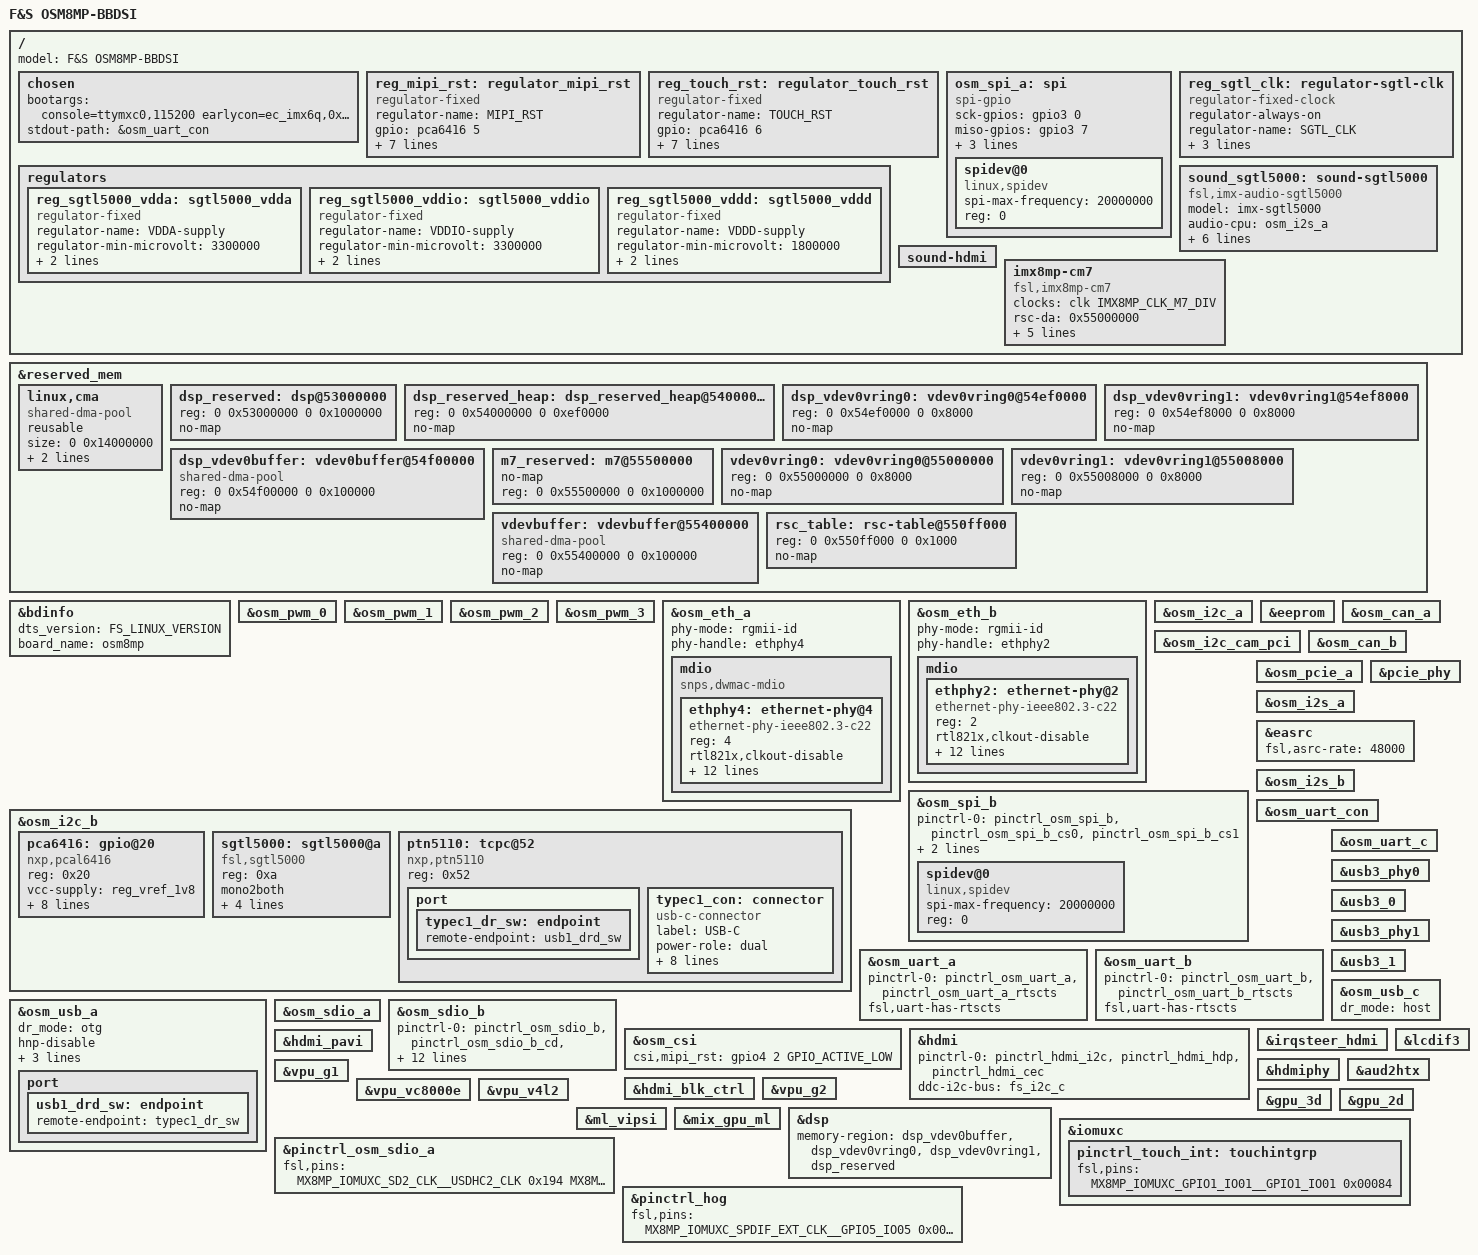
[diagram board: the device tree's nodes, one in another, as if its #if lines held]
/*
 * Copyright (C) 2025 F&S Elektronik Systeme GmbH
 *
 * This program is free software; you can redistribute it and/or modify
 * it under the terms of the GNU General Public License version 2 as
 * published by the Free Software Foundation.
 */

/dts-v1/;

/* Set board revision as 3-digit number, e.g. 110 for board rev. 1.10 */
#define CONFIG_OSM8MP_BOARD_REVISION	110
/* Set adapter revision as 3-digit number, e.g. 110 for board rev. 1.10 */
#define CONFIG_ADP_OSM_BOARD_REVISION	130
/* Set baseboard revision as 3-digit number, e.g. 110 for board rev. 1.10 */
#define CONFIG_PICOCOREBBDSI_BOARD_REVISION	140

/* Activate this if you want to use the Cortex-M4 core */
//#define SUPPORT_M4

/* Display device-trees enables MIPI DSI */
/* MIPI DSI */
//#define CONFIG_OSM8MP_MIPI_DSI

/* CAN */
#define CONFIG_OSM8MP_CAN_A
//#define CONFIG_OSM8MP_CAN_B

/* Network */
#define CONFIG_OSM8MP_ETH_A
#define CONFIG_OSM8MP_ETH_B

/* USB */
#define CONFIG_OSM8MP_USB_A
#define CONFIG_OSM8MP_USB_A_USBC
#define CONFIG_OSM8MP_USB_A_USBC_ALERT
//#define CONFIG_OSM8MP_USB_C

/* PCIe */
#define CONFIG_OSM8MP_PCIE_A

/* I2C */
#define CONFIG_OSM8MP_I2C_A /* OSM: EEPROM BB: I2C_A */
#define CONFIG_OSM8MP_I2C_B /* ADP: SGTL5000 BB: I2C_D */
/* OSM: I2C_CAM_PCI ADP: I2C_CAM  BB: I2C_B */
/* OSM: I2C_CAM_PCI ADP: MPCIE_SM BB: I2C_C */
#define CONFIG_OSM8MP_I2C_CAM_PCI

/* PWM and backlight brightness */
//#define CONFIG_OSM8MP_BL_CTRL
#define CONFIG_OSM8MP_PWM_0
#define CONFIG_OSM8MP_PWM_1

/* UART_CON - ttymxc0 */
#define CONFIG_OSM8MP_UART_CON

/* UART_A - ttymxc1 - Not connected */
//#define CONFIG_OSM8MP_UART_A
//#define CONFIG_OSM8MP_UART_A_RTSCTS

/* UART_B - ttymxc2 */
#define CONFIG_OSM8MP_UART_B
#define CONFIG_OSM8MP_UART_B_RTSCTS

/* UART_C - ttymxc3 */
#define CONFIG_OSM8MP_UART_C

/* FSPI (Single/Dual/Quad) -> Uncommented because of SPI-GPIO */
//#define CONFIG_OSM8MP_SPI_A
#define CONFIG_OSM8MP_SPI_B

/* Audio */
#define CONFIG_OSM8MP_I2S_A
//#define CONFIG_OSM8MP_I2S_B

#define CONFIG_OSM8MP_SGTL5000_AUDIO

/* Camera on serial MIPI CSI interface */
#define CONFIG_OSM8MP_SERIAL_CAMERA
/* Experimental implementation for Basler dart daA3840-30mci.
 * Define CONFIG_OSM8MP_SERIAL_CAMERA must also be set.
 */

/* SDIO */
#define CONFIG_OSM8MP_SDIO_A
#define CONFIG_OSM8MP_SDIO_A_CD
#define CONFIG_OSM8MP_SDIO_A_WP

//#define CONFIG_OSM8MP_SDIO_B
//#define CONFIG_OSM8MP_SDIO_B_CD
//#define CONFIG_OSM8MP_SDIO_B_WP
//#define CONFIG_OSM8MP_SDIO_B_8_Bit

/* Check for invalid CONFIG combinations */

/*
 * Exclude devices from Linux that are used by the Cortex-M4 FreeRTOS examples
 *
 * - UART_D: Debug Console for Cortex-M4
 * - I2C_A:  I2C Bus used in I2C examples
 * - I2C_D:  I2C Bus used by the Audio Codec in SAI examples
 * - SPI_B:  SPI_B is used for ECSPI examples
 * - SDMA1:  Gets removed at another Point, it is used by SPI_B and UART driver
 *           examples
 * - SPI_A:  SPI_A using SDMA1 but SDMA1 is excluded so also exclude SPI_A
 *
 * In addition the following pins are already predefined in FreeRTOS to be used
 * as arbitrary GPIOs. Please remove the comment of the appropriate line of
 * each device from which you use any signal in your own application.
 *
 * - AUDIO_3: GPT capture driver example uses one of its Pins
 */
#ifdef SUPPORT_M4
#undef CONFIG_OSM8MP_UART_C
//#undef CONFIG_OSM8MP_I2C_A
//#undef CONFIG_OSM8MP_SPI_A
//#undef CONFIG_OSM8MP_SPI_B
/* Only undef if using audio/sai examples */
//#undef CONFIG_OSM8MP_I2C_B
//#undef CONFIG_OSM8MP_I2S_A
#endif

/* Disable PWM_0 if BL_CTRL is enabled */
#ifdef CONFIG_OSM8MP_BL_CTRL
#undef CONFIG_OSM8MP_PWM_0
#endif

/* Disable PWM_2 if SPI_A_CS1 is enabled */
#ifdef CONFIG_OSM8MP_SPI_A_CS1
#undef CONFIG_OSM8MP_PWM_2
#endif

/* Disable PWM_2 if SPI_B_CS1 is enabled */
#ifdef CONFIG_OSM8MP_SPI_B_CS1
#undef CONFIG_OSM8MP_PWM_3
#endif

/* Set different settings for corresponding baseboard revision */
#if CONFIG_PICOCOREBBDSI_BOARD_REVISION < 130
#undef CONFIG_OSM8MP_USB_A_USBC
#endif

#if !defined(CONFIG_OSM8MP_USB_A_USBC) \
    || (CONFIG_PICOCOREBBDSI_BOARD_REVISION < 140)
#undef CONFIG_OSM8MP_USB_A_USBC_ALERT
#endif


#include "osm8mp.dts"
#include <fsversion.h>
/ {
	model = "F&S OSM8MP-BBDSI";

	chosen {
		bootargs = "console=ttymxc0,115200 earlycon=ec_imx6q,0x30890000,115200";
		stdout-path = &osm_uart_con;
	};

	reg_mipi_rst: regulator_mipi_rst {
		compatible = "regulator-fixed";
		regulator-name = "MIPI_RST";
		gpio = <&pca6416 5 GPIO_ACTIVE_HIGH>;
		regulator-min-microvolt = <3300000>;
		regulator-max-microvolt = <3300000>;
		regulator-boot-on;
		regulator-always-on;
		enable-active-high;
		startup-delay-us = <1000>;
		off-on-delay-us = <12000>;
	};

	reg_touch_rst: regulator_touch_rst {
		compatible = "regulator-fixed";
		regulator-name = "TOUCH_RST";
		gpio = <&pca6416 6 GPIO_ACTIVE_HIGH>;
		regulator-min-microvolt = <3300000>;
		regulator-max-microvolt = <3300000>;
		regulator-boot-on;
		regulator-always-on;
		enable-active-high;
		startup-delay-us = <1000>;
		off-on-delay-us = <12000>;
	};

};

&reserved_mem {
	#address-cells = <2>;
	#size-cells = <2>;
	ranges;

	linux,cma {
		compatible = "shared-dma-pool";
		reusable;
		size = <0 0x14000000>;
		alloc-ranges = <0 0x40000000 0 0x40000000>;
		linux,cma-default;
	};
};

&bdinfo{
	dts_version = FS_LINUX_VERSION;
	board_name = "osm8mp";
};

#if defined(CONFIG_OSM8MP_BL_CTRL) || defined(CONFIG_OSM8MP_PWM_0)
&osm_pwm_0 { status = "okay"; };
#endif /* CONFIG_OSM8MP_BL_CTRL || CONFIG_OSM8MP_PWM_0 */

#ifdef CONFIG_OSM8MP_PWM_1
&osm_pwm_1 { status = "okay"; };
#endif /* CONFIG_OSM8MP_PWM_1 */

#ifdef CONFIG_OSM8MP_PWM_2
&osm_pwm_2 { status = "okay"; };
#endif /* CONFIG_OSM8MP_PWM_2 */

#ifdef CONFIG_OSM8MP_PWM_3
&osm_pwm_3 { status = "okay"; };
#endif /* CONFIG_OSM8MP_PWM_3 */

#ifdef CONFIG_OSM8MP_ETH_A
&osm_eth_a {
	phy-mode = "rgmii-id";
	phy-handle = <&ethphy4>;
	status = "okay";

	mdio {
		compatible = "snps,dwmac-mdio";
		#address-cells = <1>;
		#size-cells = <0>;

		ethphy4: ethernet-phy@4 {
			compatible = "ethernet-phy-ieee802.3-c22";
			reg = <4>;
			rtl821x,clkout-disable;
			rtl821x,aldps-enable;
			rtl821x,ssc-rxc-enable;
			rtl821x,ssc-sysclk-enable;
			rtl821x,ssc-clkout-enable;
			rtl821x,led-link = <2>; // LED1 for link indication
			rtl821x,led-act = <2>; // LED1 for activity
			reset-gpios = <&pca6416 0 GPIO_ACTIVE_LOW>;
			reset-assert-us = <10000>;
			reset-deassert-us = <100000>;
			interrupt-parent = <&pca6416>;
			interrupts = <2 IRQ_TYPE_EDGE_FALLING>;
			eee-broken-1000t;
		};
	};
};
#endif /* CONFIG_OSM8MP_ETH_A */

#ifdef CONFIG_OSM8MP_ETH_B
&osm_eth_b {
	phy-mode = "rgmii-id";
	phy-handle = <&ethphy2>;
	status = "okay";

	mdio {
		#address-cells = <1>;
		#size-cells = <0>;

		ethphy2: ethernet-phy@2 {
			compatible = "ethernet-phy-ieee802.3-c22";
			reg = <2>;
			rtl821x,clkout-disable;
			rtl821x,aldps-enable;
			rtl821x,ssc-rxc-enable;
			rtl821x,ssc-sysclk-enable;
			rtl821x,ssc-clkout-enable;
			rtl821x,led-link = <2>; // LED1 for link indication
			rtl821x,led-act = <2>; // LED1 for activity
			reset-gpios = <&pca6416 1 GPIO_ACTIVE_LOW>;
			reset-assert-us = <10000>;
			reset-deassert-us = <100000>;
			interrupt-parent = <&pca6416>;
			interrupts = <3 IRQ_TYPE_EDGE_FALLING>;
			eee-broken-1000t;
		};
	};
};
#endif /* CONFIG_OSM8MP_ETH_B */

#ifdef CONFIG_OSM8MP_I2C_A
&osm_i2c_a { status = "okay"; };
#ifdef CONFIG_OSM8MP_EEPROM
&eeprom { status = "okay"; };
#endif /* CONFIG_OSM8MP_EEPROM */
#endif /* CONFIG_OSM8MP_I2C_A */

#ifdef CONFIG_OSM8MP_I2C_B
&osm_i2c_b { status = "okay"; };
#if CONFIG_ADP_OSM_BOARD_REVISION >= 130
&osm_i2c_b {
	/* GPIO expander */
	pca6416: gpio@20 {
		compatible = "nxp,pcal6416";
		reg = <0x20>;
		vcc-supply = <&reg_vref_1v8>;
		gpio-controller;
		#gpio-cells = <2>;
		interrupt-controller;
		#interrupt-cells = <2>;
		interrupt-parent = <&gpio1>;
		interrupts = <6 IRQ_TYPE_LEVEL_LOW>;
		/* Enable Open-Drain for Port 0 and 1 */
		pcal6416,open-drain;
		gpio-line-names =
		/*  0 */ "", "", "", "",
		/*  4 */ "AUDIO_B_I2S_RXFS", "GPIO_J1_7", "GPIO_J1_2", "BL_ON",
		/*  8 */ "VLCD_ON", "GPIO_J1_44", "GPIO_J1_46", "",
		/* 12 */ "", "", "", "";
		status = "okay";
	};
};
#endif /* CONFIG_ADP_OSM_BOARD_REVISION >= 130 */
#endif /* CONFIG_OSM8MP_I2C_B */

#ifdef CONFIG_OSM8MP_I2C_CAM_PCI
&osm_i2c_cam_pci { status = "okay"; };
#endif /* CONFIG_OSM8MP_I2C_CAM_PCI */

#ifdef CONFIG_OSM8MP_SPI_A
/ {
	/* osm_spi_a overwritten by SPI bitbanging driver */
	/delete-node/ &osm_spi_a;
	/* SPI bitbanging driver */
	osm_spi_a: spi {
		compatible = "spi-gpio";
		#address-cells = <0x1>;
		#size-cells = <0x0>;

		sck-gpios = <&gpio3 0 0>;
		miso-gpios = <&gpio3 7 0>;
		mosi-gpios = <&gpio3 6 0>;
		cs-gpios = <&gpio3 1 0>;
		num-chipselects = <1>;

		spidev@0 {
			compatible = "linux,spidev";
			spi-max-frequency = <20000000>;
			reg = <0>;
			status = "okay";
		};
	};
};
#endif /* CONFIG_OSM8MP_SPI_A */

#ifdef CONFIG_OSM8MP_SPI_B
&osm_spi_b {
#ifdef CONFIG_OSM8MP_SPI_B_CS1
	pinctrl-0 = <&pinctrl_osm_spi_b &pinctrl_osm_spi_b_cs0 &pinctrl_osm_spi_b_cs1>;
	cs-gpios = <&gpio5 13 GPIO_ACTIVE_LOW>, <&gpio3 20 GPIO_ACTIVE_LOW>;
	num-cs = <2>;
#else
	pinctrl-0 = <&pinctrl_osm_spi_b &pinctrl_osm_spi_b_cs0>;
	cs-gpios = <&gpio5 13 GPIO_ACTIVE_LOW>;
	num-cs = <1>;
#endif
	status = "okay";

	spidev@0 {
		compatible = "linux,spidev";
		spi-max-frequency = <20000000>;
		reg = <0>;
		status = "okay";
	};
};
#endif


#ifdef CONFIG_OSM8MP_CAN_A
&osm_can_a { status = "okay"; };
#endif /* CONFIG_OSM8MP_CAN_A */

#ifdef CONFIG_OSM8MP_CAN_B
&osm_can_b { status = "okay"; };
#endif /* CONFIG_OSM8MP_CAN_B */

#ifdef CONFIG_OSM8MP_PCIE_A
&osm_pcie_a{ status = "okay";};
&pcie_phy{ status = "okay";};
#endif /* CONFIG_OSM8MP_PCIE_A */

#ifdef CONFIG_OSM8MP_I2S_A
&osm_i2s_a { status = "okay"; };

#ifdef CONFIG_OSM8MP_SGTL5000_AUDIO
/{
	regulators {
		/* SGTL5000 analog voltage */
		reg_sgtl5000_vdda: sgtl5000_vdda {
			compatible = "regulator-fixed";
			regulator-name = "VDDA-supply";
			regulator-min-microvolt = <3300000>;
			regulator-max-microvolt = <3300000>;
			regulator-always-on;
		};

		/* SGTL5000 I/O voltage */
		reg_sgtl5000_vddio: sgtl5000_vddio {
			compatible = "regulator-fixed";
			regulator-name = "VDDIO-supply";
			regulator-min-microvolt = <3300000>;
			regulator-max-microvolt = <3300000>;
			regulator-always-on;
		};

		/* SGTL5000 internal digital voltage */
		reg_sgtl5000_vddd: sgtl5000_vddd {
			compatible = "regulator-fixed";
			regulator-name = "VDDD-supply";
			regulator-min-microvolt = <1800000>;
			regulator-max-microvolt = <1800000>;
			regulator-always-on;
		};
	};

	reg_sgtl_clk: regulator-sgtl-clk {
			compatible = "regulator-fixed-clock";
			regulator-always-on;
			regulator-name = "SGTL_CLK";
			clocks = <&clk IMX8MP_CLK_CLKOUT1>;
			assigned-clocks = <&clk IMX8MP_CLK_CLKOUT1>;
			assigned-clock-rates = <24576000>;
	};

	sound_sgtl5000: sound-sgtl5000 {
		compatible = "fsl,imx-audio-sgtl5000";
		model = "imx-sgtl5000";
		audio-cpu = <&osm_i2s_a>;
		audio-codec = <&sgtl5000>;
		audio-asrc = <&easrc>;
		audio-routing =
			"LINE_IN", "Line In Jack",
			"Mic Jack", "Mic Bias",
			"MIC_IN", "Mic Jack",
			"Line Out Jack", "LINE_OUT",
			"Headphone Jack", "HP_OUT";
	};
};

&osm_i2c_b {
	status = "okay";
	sgtl5000: sgtl5000@a {
		compatible = "fsl,sgtl5000";
		reg = <0xa>;
		mono2both;
		clocks = <&clk IMX8MP_CLK_CLKOUT1>;
		VDDA-supply = <&reg_sgtl5000_vdda>;
		VDDIO-supply = <&reg_sgtl5000_vddio>;
		VDDD-supply = <&reg_sgtl5000_vddd>;
	};
};

&easrc {
	fsl,asrc-rate  = <48000>;
	status = "okay";
};
#endif /* CONFIG_OSM8MP_SGTL5000_AUDIO */
#endif /* CONFIG_OSM8MP_I2S_A */

#ifdef CONFIG_OSM8MP_I2S_B
&osm_i2s_b { status = "okay"; };
#endif /* CONFIG_OSM8MP_I2S_B */

#ifdef CONFIG_OSM8MP_UART_CON
&osm_uart_con { status = "okay"; };
#endif /* CONFIG_OSM8MP_UART_CON */

#ifdef CONFIG_OSM8MP_UART_A
&osm_uart_a {
#ifdef CONFIG_OSM8MP_UART_A_RTSCTS
	pinctrl-0 = <&pinctrl_osm_uart_a &pinctrl_osm_uart_a_rtscts>;
	fsl,uart-has-rtscts;
#endif
	status = "okay";
};
#endif /* CONFIG_OSM8MP_UART_A */

#ifdef CONFIG_OSM8MP_UART_B
&osm_uart_b {
#ifdef CONFIG_OSM8MP_UART_B_RTSCTS
	pinctrl-0 = <&pinctrl_osm_uart_b &pinctrl_osm_uart_b_rtscts>;
	fsl,uart-has-rtscts;
#endif
	status = "okay";
};
#endif /* CONFIG_OSM8MP_UART_B */

#ifdef CONFIG_OSM8MP_UART_C
&osm_uart_c { status = "okay"; };
#endif /* CONFIG_OSM8MP_UART_C */

#ifdef CONFIG_OSM8MP_USB_A
&usb3_phy0 { status = "okay"; };

&usb3_0 { status = "okay"; };

&osm_usb_a {
	dr_mode = "otg";
#ifdef CONFIG_OSM8MP_USB_A_USBC
	hnp-disable;
	srp-disable;
	adp-disable;
	usb-role-switch;
	status = "okay";
	port {
		usb1_drd_sw: endpoint {
			remote-endpoint = <&typec1_dr_sw>;
		};
	};
#endif
};

#ifdef CONFIG_OSM8MP_USB_A_USBC
&osm_i2c_b {
	/* USB-C */
	ptn5110: tcpc@52 {
		compatible = "nxp,ptn5110";
#ifdef CONFIG_OSM8MP_USB_A_USBC_ALERT
#if CONFIG_ADP_OSM_BOARD_REVISION < 130
		interrupt-parent = <&gpio1>;
		interrupts = <10 IRQ_TYPE_LEVEL_LOW>;
#endif
#endif
		reg = <0x52>;
		status = "okay";

		port {
			typec1_dr_sw: endpoint {
				remote-endpoint = <&usb1_drd_sw>;
			};
		};

		typec1_con: connector {
			compatible = "usb-c-connector";
			label = "USB-C";
			power-role = "dual";
			data-role = "dual";
			try-power-role = "sink";
			source-pdos = <PDO_FIXED(5000, 3000,
			PDO_FIXED_USB_COMM)>;
			sink-pdos = <PDO_FIXED(5000, 3000, PDO_FIXED_USB_COMM)
				     PDO_VAR(5000, 20000, 3000)>;
			op-sink-microwatt = <15000000>;
			self-powered;
		};
	};
};
#endif  /* CONFIG_OSM8MP_USB_A_USBC */
#endif  /* CONFIG_OSM8MP_USB_A */

#ifdef CONFIG_OSM8MP_USB_C
&usb3_phy1 {
	status = "okay";
};

&usb3_1 {
	status = "okay";
};

&osm_usb_c {
	dr_mode = "host";
	status = "okay";
};
#endif /* CONFIG_OSM8MP_USB_C */

#ifdef CONFIG_OSM8MP_SDIO_A
&osm_sdio_a { status = "okay"; };
#endif /* CONFIG_OSM8MP_SDIO_A */

#ifdef CONFIG_OSM8MP_SDIO_B
&osm_sdio_b {
	pinctrl-0 = <&pinctrl_osm_sdio_b>, <&pinctrl_osm_sdio_b_cd>, <&pinctrl_osm_sdio_b_wp>, <&pinctrl_osm_sdio_b_rst>;
	pinctrl-1 = <&pinctrl_osm_sdio_b_100mhz>, <&pinctrl_osm_sdio_b_cd>, <&pinctrl_osm_sdio_b_wp>, <&pinctrl_osm_sdio_b_rst>;
	pinctrl-2 = <&pinctrl_osm_sdio_b_200mhz>, <&pinctrl_osm_sdio_b_cd>, <&pinctrl_osm_sdio_b_wp>, <&pinctrl_osm_sdio_b_rst>;
	vqmmc-supply = <&reg_vref_1v8>;
#ifdef CONFIG_OSM8MP_SDIO_B_8_Bit
	bus-width = <8>;
#else
	bus-width = <4>;
#endif
	status = "okay";
};
#endif

#ifdef CONFIG_OSM8MP_SERIAL_CAMERA
&osm_csi {
	status = "okay";
	csi,mipi_rst = <&gpio4 2 GPIO_ACTIVE_LOW>;
};
#endif

#ifdef CONFIG_OSM8MP_HDMI
&hdmi {

pinctrl-0 =<
#ifdef CONFIG_OSM8MP_HDMI_I2C
			&pinctrl_hdmi_i2c
#endif
#ifdef CONFIG_OSM8MP_HDMI_HPD
			&pinctrl_hdmi_hdp
#endif
#ifdef CONFIG_OSM8MP_HDMI_CEC
			&pinctrl_hdmi_cec
#endif
			>;

#ifndef CONFIG_OSM8MP_HDMI_I2C
	ddc-i2c-bus = <&fs_i2c_c>;
#endif
	status = "okay";

};

&irqsteer_hdmi { status = "okay"; };
&hdmi_pavi { status = "okay"; };
&hdmi { status="okay"; };
&hdmiphy { status="okay"; };
&hdmi_blk_ctrl { status="okay"; };
&lcdif3 { status = "okay"; };

#ifdef CONFIG_OSM8MP_HDMI_AUDIO
/{
	sound-hdmi { status = "okay"; };
};
&aud2htx { status = "okay"; };
#endif /* CONFIG_OSM8MP_HDMI_AUDIO */
#endif /* CONFIG_OSM8MP_HDMI */

#ifdef CONFIG_OSM8MP_VPU
&vpu_g1 { status = "okay"; };
&vpu_g2 { status = "okay"; };
&vpu_vc8000e { status = "okay"; };
&vpu_v4l2 { status = "okay"; };
#endif /* CONFIG_OSM8MP_VPU */

#ifdef CONFIG_OSM8MP_GPU
&gpu_3d { status = "okay"; };
&gpu_2d { status = "okay"; };
#endif /* CONFIG_OSM8MP_GPU */

#ifdef CONFIG_OSM8MP_ML
&ml_vipsi { status = "okay"; };
&mix_gpu_ml { status = "okay"; };
#endif /* CONFIG_OSM8MP_ML */

#ifdef CONFIG_OSM8MP_DSP
&reserved_mem {
	dsp_reserved: dsp@53000000 {
		reg = <0 0x53000000 0 0x1000000>;
		no-map;
	};
	dsp_reserved_heap: dsp_reserved_heap@54000000 {
		reg = <0 0x54000000 0 0xef0000>;
		no-map;
	};
	dsp_vdev0vring0: vdev0vring0@54ef0000 {
		reg = <0 0x54ef0000 0 0x8000>;
		no-map;
	};
	dsp_vdev0vring1: vdev0vring1@54ef8000 {
		reg = <0 0x54ef8000 0 0x8000>;
		no-map;
	};
	dsp_vdev0buffer: vdev0buffer@54f00000{
		compatible = "shared-dma-pool";
		reg = <0 0x54f00000 0 0x100000>;
		no-map;
	};
};

&dsp {
	memory-region = <&dsp_vdev0buffer>, <&dsp_vdev0vring0>,
			<&dsp_vdev0vring1>, <&dsp_reserved>;
	status = "okay";
};
#endif /* CONFIG_OSM8MP_DSP */

#ifdef SUPPORT_M7
&reserved_mem {
	#address-cells = <2>;
	#size-cells = <2>;
	ranges;

		m7_reserved: m7@55500000 {
			no-map;
			reg = <0 0x55500000 0 0x1000000>;
		};

		vdev0vring0: vdev0vring0@55000000 {
			reg = <0 0x55000000 0 0x8000>;
			no-map;
		};

		vdev0vring1: vdev0vring1@55008000 {
			reg = <0 0x55008000 0 0x8000>;
			no-map;
		};

		vdevbuffer: vdevbuffer@55400000 {
			compatible = "shared-dma-pool";
			reg = <0 0x55400000 0 0x100000>;
			no-map;
		};

		rsc_table: rsc-table@550ff000 {
			reg = <0 0x550ff000 0 0x1000>;
			no-map;
		};
};

/ {
	imx8mp-cm7 {
		compatible = "fsl,imx8mp-cm7";
		clocks = <&clk IMX8MP_CLK_M7_DIV>;
		rsc-da = <0x55000000>;
		mbox-names = "tx", "rx", "rxdb";
		mboxes = <&mu 0 1
			  &mu 1 1
			  &mu 3 1>;
		memory-region = <&m7_reserved>, <&vdevbuffer>, <&vdev0vring0>, <&vdev0vring1>, <&rsc_table>;
		status = "okay";
		fsl,startup-delay-ms = <500>;
	};
};
#endif /* SUPPORT_M7 */

&iomuxc {
	pinctrl_touch_int: touchintgrp {
		fsl,pins = <
			MX8MP_IOMUXC_GPIO1_IO01__GPIO1_IO01	0x00084
		>;
	};
};

/*
 * MK 2025-09-18:
 * The drive-strength for SDIO_A must be increased to compensate
 * for a longer route through the adapter (OSM -> ADP -> BB)
 */
&pinctrl_osm_sdio_a {
	fsl,pins = <
		MX8MP_IOMUXC_SD2_CLK__USDHC2_CLK	0x194
		MX8MP_IOMUXC_SD2_CMD__USDHC2_CMD	0x1d4
		MX8MP_IOMUXC_SD2_DATA0__USDHC2_DATA0	0x1d4
		MX8MP_IOMUXC_SD2_DATA1__USDHC2_DATA1	0x1d4
		MX8MP_IOMUXC_SD2_DATA2__USDHC2_DATA2	0x1d4
		MX8MP_IOMUXC_SD2_DATA3__USDHC2_DATA3	0x1d4
	>;
};

&pinctrl_hog {
	fsl,pins = <
		/* CARRIER_PWR_EN */
		MX8MP_IOMUXC_SPDIF_EXT_CLK__GPIO5_IO05	0x00004

		/* GPIO_A */
#ifndef IMX8MP_TOUCH_INTERRUPT_PINCTRL
		/* 0 */ MX8MP_IOMUXC_GPIO1_IO05__GPIO1_IO05	0x00004
		/* 3 */ MX8MP_IOMUXC_GPIO1_IO01__GPIO1_IO01	0x00004
#else
#if CONFIG_ADP_OSM_BOARD_REVISION < 130
		/* 0 */ MX8MP_IOMUXC_GPIO1_IO05__GPIO1_IO05	0x00004
#else
		/* 3 */ MX8MP_IOMUXC_GPIO1_IO01__GPIO1_IO01	0x00004
#endif
#endif
		/* 1 */ MX8MP_IOMUXC_GPIO1_IO06__GPIO1_IO06	0x00004
		/* 2 */ MX8MP_IOMUXC_GPIO1_IO07__GPIO1_IO07	0x00004
		/* 4 */ MX8MP_IOMUXC_GPIO1_IO10__GPIO1_IO10	0x00004
		/* 5 */ MX8MP_IOMUXC_GPIO1_IO08__GPIO1_IO08	0x00004
#ifndef CONFIG_OSM8MP_PWM_2
#ifndef CONFIG_OSM8MP_SPI_A_CS1
		/* 6 */ MX8MP_IOMUXC_SAI5_RXD0__GPIO3_IO21	0x00004
#endif
#endif
#ifndef CONFIG_OSM8MP_PWM_3
#ifndef CONFIG_OSM8MP_SPI_B_CS1
		/* 7 */ MX8MP_IOMUXC_SAI5_RXC__GPIO3_IO20	0x00004
#endif
#endif
		/* GPIO_B */
		/* 0 */ MX8MP_IOMUXC_GPIO1_IO03__GPIO1_IO03	0x00004
		/* 1 */ MX8MP_IOMUXC_GPIO1_IO11__GPIO1_IO11	0x00004
		/* 2 */ MX8MP_IOMUXC_GPIO1_IO00__GPIO1_IO00	0x00004
		/* 3 */ MX8MP_IOMUXC_GPIO1_IO09__GPIO1_IO09	0x00004
		/* 4 */ MX8MP_IOMUXC_SAI5_RXD3__GPIO3_IO24	0x00004
		/* 5 */ MX8MP_IOMUXC_SAI2_RXC__GPIO4_IO22	0x00004
		/* 6 */ MX8MP_IOMUXC_SAI5_RXD2__GPIO3_IO23	0x00004
		/* 7 */ MX8MP_IOMUXC_SAI2_RXFS__GPIO4_IO21	0x00004

		/* GPIO_C */
		/* 0 */ MX8MP_IOMUXC_SAI2_MCLK__GPIO4_IO27	0x00004
		/* 1 */ MX8MP_IOMUXC_SAI1_RXD1__GPIO4_IO03	0x00004
		/* 2 */ MX8MP_IOMUXC_SAI1_TXD7__GPIO4_IO19	0x00004
		/* 3 */ MX8MP_IOMUXC_SAI1_TXD6__GPIO4_IO18	0x00004
		/* 4 */ /* VDD_EN: Disable display for usage */
		/* 4 */ MX8MP_IOMUXC_SAI1_RXFS__GPIO4_IO00	0x00004
		/* 5 */ /* BL_EN: Disable backlight control for usage */
		/* 5 */ MX8MP_IOMUXC_SAI1_MCLK__GPIO4_IO20	0x00004
		/* 6 */ /* CAM_EN: Disable CAM for usage */
		/* 6 */ MX8MP_IOMUXC_SAI1_RXC__GPIO4_IO01	0x00004
		/* 7 */ /* CAM_RST: Disable CAM for usage */
		/* 7 */ MX8MP_IOMUXC_SAI1_RXD0__GPIO4_IO02	0x00004

#if !defined(CONFIG_OSM8MP_BL_CTRL) && !defined(CONFIG_OSM8MP_PWM_0)
		MX8MP_IOMUXC_SAI5_RXFS__GPIO3_IO19	0x00004
#endif

#ifndef CONFIG_OSM8MP_PWM_1
		MX8MP_IOMUXC_SAI5_MCLK__GPIO3_IO25	0x00004
#endif

#ifndef CONFIG_OSM8MP_SPI_A
		MX8MP_IOMUXC_NAND_ALE__GPIO3_IO00		0x00004
		MX8MP_IOMUXC_NAND_DATA00__GPIO3_IO06	0x00004
		MX8MP_IOMUXC_NAND_DATA01__GPIO3_IO07	0x00004
		MX8MP_IOMUXC_NAND_DATA02__GPIO3_IO08	0x00004
		MX8MP_IOMUXC_NAND_DATA03__GPIO3_IO09	0x00004
		MX8MP_IOMUXC_NAND_CE0_B__GPIO3_IO01		0x00004
#endif
#ifndef CONFIG_OSM8MP_SPI_A_HIGHSPEED
		/* Enable DSI_TE functionality */
		MX8MP_IOMUXC_NAND_DQS__GPIO3_IO14		0x00004
#endif

#ifndef CONFIG_OSM8MP_SPI_B
		MX8MP_IOMUXC_ECSPI2_SCLK__GPIO5_IO10	0x00004
		MX8MP_IOMUXC_ECSPI2_MOSI__GPIO5_IO11	0x00004
		MX8MP_IOMUXC_ECSPI2_MISO__GPIO5_IO12	0x00004
		MX8MP_IOMUXC_ECSPI1_SS0__GPIO5_IO09		0x00004
#endif

#ifndef CONFIG_OSM8MP_ETH_A
		MX8MP_IOMUXC_ENET_MDC__GPIO1_IO16		0x00004
		MX8MP_IOMUXC_ENET_MDIO__GPIO1_IO17		0x00004
		MX8MP_IOMUXC_ENET_RD0__GPIO1_IO26		0x00004
		MX8MP_IOMUXC_ENET_RD1__GPIO1_IO27		0x00004
		MX8MP_IOMUXC_ENET_RD2__GPIO1_IO28		0x00004
		MX8MP_IOMUXC_ENET_RD3__GPIO1_IO29		0x00004
		MX8MP_IOMUXC_ENET_RXC__GPIO1_IO25		0x00004
		MX8MP_IOMUXC_ENET_RX_CTL__GPIO1_IO24	0x00004
		MX8MP_IOMUXC_ENET_TD0__GPIO1_IO21		0x00004
		MX8MP_IOMUXC_ENET_TD1__GPIO1_IO20		0x00004
		MX8MP_IOMUXC_ENET_TD2__GPIO1_IO19		0x00004
		MX8MP_IOMUXC_ENET_TD3__GPIO1_IO18		0x00004
		MX8MP_IOMUXC_ENET_TX_CTL__GPIO1_IO22	0x00004
		MX8MP_IOMUXC_ENET_TXC__GPIO1_IO23		0x00004
#endif

#ifndef CONFIG_OSM8MP_ETH_B
		MX8MP_IOMUXC_SAI1_RXD2__GPIO4_IO04	0x00004
		MX8MP_IOMUXC_SAI1_RXD3__GPIO4_IO05	0x00004
		MX8MP_IOMUXC_SAI1_RXD4__GPIO4_IO06	0x00004
		MX8MP_IOMUXC_SAI1_RXD5__GPIO4_IO07	0x00004
		MX8MP_IOMUXC_SAI1_RXD6__GPIO4_IO08	0x00004
		MX8MP_IOMUXC_SAI1_RXD7__GPIO4_IO09	0x00004
		MX8MP_IOMUXC_SAI1_TXC__GPIO4_IO11	0x00004
		MX8MP_IOMUXC_SAI1_TXFS__GPIO4_IO10	0x00004
		MX8MP_IOMUXC_SAI1_TXD0__GPIO4_IO12	0x00004
		MX8MP_IOMUXC_SAI1_TXD1__GPIO4_IO13	0x00004
		MX8MP_IOMUXC_SAI1_TXD2__GPIO4_IO14	0x00004
		MX8MP_IOMUXC_SAI1_TXD3__GPIO4_IO15	0x00004
		MX8MP_IOMUXC_SAI1_TXD4__GPIO4_IO16	0x00004
		MX8MP_IOMUXC_SAI1_TXD5__GPIO4_IO17	0x00004
#endif

#ifndef CONFIG_OSM8MP_CAN_A
		MX8MP_IOMUXC_SPDIF_RX__GPIO5_IO04	0x00004
		MX8MP_IOMUXC_SPDIF_TX__GPIO5_IO03	0x00004
#endif

#ifndef CONFIG_OSM8MP_CAN_B
		MX8MP_IOMUXC_HDMI_HPD__GPIO3_IO29	0x00004
		MX8MP_IOMUXC_HDMI_CEC__GPIO3_IO28	0x00004
#endif

#ifndef CONFIG_OSM8MP_I2C_A
		MX8MP_IOMUXC_I2C3_SCL__GPIO5_IO18		0x00004
		MX8MP_IOMUXC_I2C3_SDA__GPIO5_IO19		0x00004
#endif

#ifndef CONFIG_OSM8MP_I2C_B
		MX8MP_IOMUXC_I2C4_SCL__GPIO5_IO20		0x00004
		MX8MP_IOMUXC_I2C4_SDA__GPIO5_IO21		0x00004
#endif

#ifndef CONFIG_OSM8MP_I2C_CAM_PCI
		MX8MP_IOMUXC_HDMI_DDC_SCL__GPIO3_IO26	0x00004
		MX8MP_IOMUXC_HDMI_DDC_SDA__GPIO3_IO27	0x00004
#endif

#ifndef CONFIG_OSM8MP_PCIE_A
		MX8MP_IOMUXC_SAI5_RXD1__GPIO3_IO22		0x00004
		MX8MP_IOMUXC_SAI3_RXC__GPIO4_IO29		0x00004
		MX8MP_IOMUXC_SAI3_RXFS__GPIO4_IO28		0x00004
		MX8MP_IOMUXC_NAND_CE1_B__GPIO3_IO02		0x00004
#endif

#ifndef CONFIG_OSM8MP_I2S_A
		MX8MP_IOMUXC_SAI2_TXFS__GPIO4_IO24	0x00004
		MX8MP_IOMUXC_SAI2_TXC__GPIO4_IO25	0x00004
		MX8MP_IOMUXC_SAI2_TXD0__GPIO4_IO26	0x00004
		MX8MP_IOMUXC_SAI2_RXD0__GPIO4_IO23	0x00004
#endif

#ifndef CONFIG_OSM8MP_I2S_B
		MX8MP_IOMUXC_SAI3_TXFS__GPIO4_IO31	0x00004
		MX8MP_IOMUXC_SAI3_TXC__GPIO5_IO00	0x00004
		MX8MP_IOMUXC_SAI3_TXD__GPIO5_IO01	0x00004
		MX8MP_IOMUXC_SAI3_RXD__GPIO4_IO30	0x00004
#endif

#ifndef CONFIG_OSM8MP_UART_A
		MX8MP_IOMUXC_UART1_RXD__GPIO5_IO22		0x00004
		MX8MP_IOMUXC_UART1_TXD__GPIO5_IO23		0x00004
#endif
#ifndef CONFIG_OSM8MP_UART_A_RTSCTS
		MX8MP_IOMUXC_UART3_RXD__GPIO5_IO26		0x00004
		MX8MP_IOMUXC_UART3_TXD__GPIO5_IO27		0x00004
#endif

#ifndef CONFIG_OSM8MP_UART_B
		MX8MP_IOMUXC_ECSPI1_SCLK__GPIO5_IO06 	0x00004
		MX8MP_IOMUXC_ECSPI1_MOSI__GPIO5_IO07	0x00004
#endif
#ifndef CONFIG_OSM8MP_UART_B_RTSCTS
		MX8MP_IOMUXC_ECSPI1_MISO__GPIO5_IO08	0x00004
		MX8MP_IOMUXC_ECSPI1_SS0__GPIO5_IO09		0x00004
#endif

#ifndef CONFIG_OSM8MP_UART_C
		MX8MP_IOMUXC_UART4_RXD__GPIO5_IO28		0x00004
		MX8MP_IOMUXC_UART4_TXD__GPIO5_IO29		0x00004
#endif

#ifndef CONFIG_OSM8MP_UART_CON
		MX8MP_IOMUXC_UART2_RXD__GPIO5_IO24		0x00004
		MX8MP_IOMUXC_UART2_TXD__GPIO5_IO25		0x00004
#endif

#ifndef CONFIG_OSM8MP_USB_A
		MX8MP_IOMUXC_GPIO1_IO12__GPIO1_IO12	0x00004
#endif

#ifndef CONFIG_OSM8MP_USB_C
		MX8MP_IOMUXC_GPIO1_IO14__GPIO1_IO14	0x00004
#endif

#ifndef CONFIG_OSM8MP_SDIO_A
		MX8MP_IOMUXC_SD2_RESET_B__GPIO2_IO19	0x00004
		MX8MP_IOMUXC_SD2_CLK__GPIO2_IO13		0x00004
		MX8MP_IOMUXC_SD2_CMD__GPIO2_IO14		0x00004
		MX8MP_IOMUXC_SD2_DATA0__GPIO2_IO15		0x00004
		MX8MP_IOMUXC_SD2_DATA1__GPIO2_IO16		0x00004
		MX8MP_IOMUXC_SD2_DATA2__GPIO2_IO17		0x00004
		MX8MP_IOMUXC_SD2_DATA3__GPIO2_IO18		0x00004
#endif
#ifndef CONFIG_OSM8MP_SDIO_A_CD
		MX8MP_IOMUXC_SD2_CD_B__GPIO2_IO12		0x00004
#endif
#ifndef CONFIG_OSM8MP_SDIO_A_WP
		MX8MP_IOMUXC_SD2_WP__GPIO2_IO20			0x00004
#endif

#ifndef CONFIG_OSM8MP_SDIO_B
			MX8MP_IOMUXC_NAND_READY_B__GPIO3_IO16	0x00004
			MX8MP_IOMUXC_NAND_WE_B__GPIO3_IO17		0x00004
			MX8MP_IOMUXC_NAND_WP_B__GPIO3_IO18		0x00004
			MX8MP_IOMUXC_NAND_DATA04__GPIO3_IO10	0x00004
			MX8MP_IOMUXC_NAND_DATA05__GPIO3_IO11	0x00004
			MX8MP_IOMUXC_NAND_DATA06__GPIO3_IO12	0x00004
			MX8MP_IOMUXC_NAND_DATA07__GPIO3_IO13	0x00004
#endif
#ifndef CONFIG_OSM8MP_SDIO_B_CD
			MX8MP_IOMUXC_I2C2_SCL__GPIO5_IO16		0x00004
#endif
#ifndef CONFIG_OSM8MP_SDIO_B_WP
			MX8MP_IOMUXC_I2C2_SDA__GPIO5_IO17		0x00004
#endif
#ifndef CONFIG_OSM8MP_SDIO_B_8_Bit
			MX8MP_IOMUXC_NAND_RE_B__GPIO3_IO15		0x00004
			MX8MP_IOMUXC_NAND_CE2_B__GPIO3_IO03		0x00004
			MX8MP_IOMUXC_NAND_CE3_B__GPIO3_IO04		0x00004
			MX8MP_IOMUXC_NAND_CLE__GPIO3_IO05		0x00004
#endif
	>;
};
